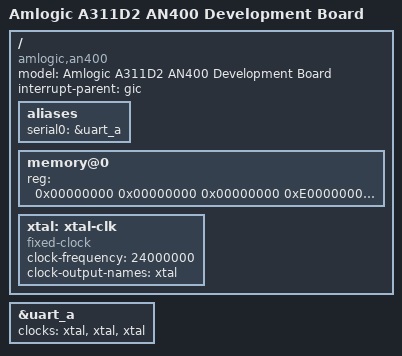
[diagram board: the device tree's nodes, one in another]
// SPDX-License-Identifier: (GPL-2.0+ OR MIT)
/*
 * Copyright (c) 2023 Amlogic, Inc. All rights reserved.
 */

/dts-v1/;

#include "amlogic-t7.dtsi"

/ {
	model = "Amlogic A311D2 AN400 Development Board";
	compatible = "amlogic,an400", "amlogic,a311d2", "amlogic,t7";
	interrupt-parent = <&gic>;
	#address-cells = <2>;
	#size-cells = <2>;

	aliases {
		serial0 = &uart_a;
	};

	memory@0 {
		device_type = "memory";
		reg = <0x00000000 0x00000000 0x00000000 0xE0000000
			0x00000001 0x00000000 0x00000000 0x20000000>;
	};

	xtal: xtal-clk {
		compatible = "fixed-clock";
		clock-frequency = <24000000>;
		clock-output-names = "xtal";
		#clock-cells = <0>;
	};
};

&uart_a {
	clocks = <&xtal>, <&xtal>, <&xtal>;
	clock-names = "xtal", "pclk", "baud";
	status = "okay";
};
